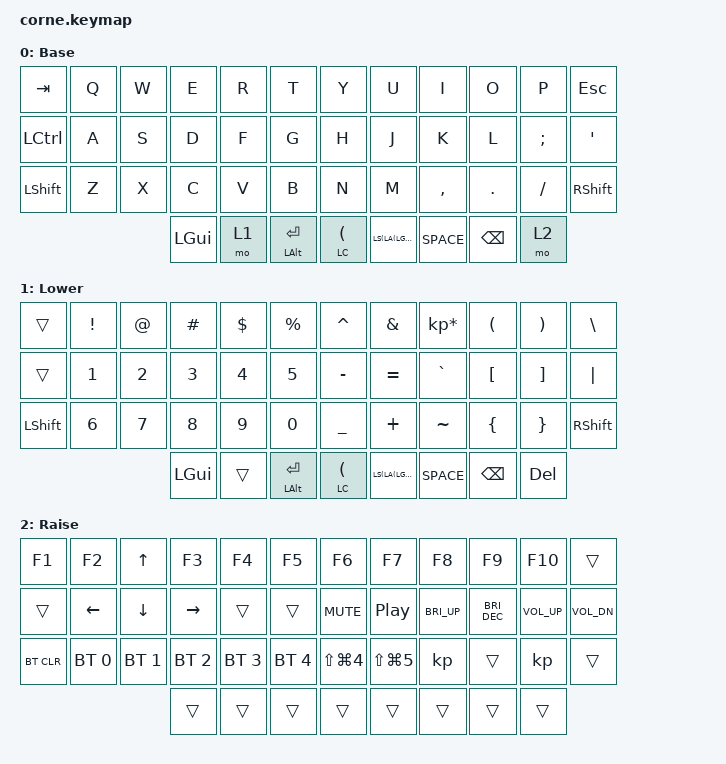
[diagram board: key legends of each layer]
/*
 * Copyright (c) 2020 The ZMK Contributors
 *
 * SPDX-License-Identifier: MIT
 */

#include <behaviors.dtsi>
#include <dt-bindings/zmk/keys.h>
#include <dt-bindings/zmk/bt.h>

/ {
    behaviors {
        tp: tap_preferred {
            compatible = "zmk,behavior-hold-tap";
            label = "TAP_PREFERRED";
            #binding-cells = <2>;
            tapping-term-ms = <150>;
            quick-tap-ms = <0>;
            flavor = "tap-preferred";
            bindings = <&kp>, <&kp>;
        }; 
    };

    keymap {
        compatible = "zmk,keymap";

        default_layer {
            // -----------------------------------------------------------------------------------------
            // | TAB  |  Q  |  W  |  E  |  R  |  T      |   |  Y        |  U   |  I  |  O  |  P  | ESC  |
            // | CTRL |  A  |  S  |  D  |  F  |  G      |   |  H        |  J   |  K  |  L  |  ;  |  SQT |
            // | SHFL |  Z  |  X  |  C  |  V  |  B      |   |  N        |  M   |  ,  |  .  |  /  | SHFR |
            //                    | GUI | LWR | ALT/ENT |   | HYPER/SPC | BKSP | RSE |

            label = "Base";
            bindings = <
   &kp TAB   &kp Q   &kp W      &kp E   &kp R      &kp T            &kp Y   &kp U      &kp I      &kp O     &kp P       &kp ESC
   &kp LCTRL &kp A   &kp S      &kp D   &kp F      &kp G            &kp H   &kp J      &kp K      &kp L     &kp SEMI    &kp SQT
   &kp LSHFT &kp Z   &kp X      &kp C   &kp V      &kp B            &kp N   &kp M      &kp COMMA  &kp DOT   &kp FSLH    &kp RSHIFT
                            &kp LGUI &mo 1 &tp LALT RET            &tp LC(LS(LA(LGUI))) SPACE &kp BSPC &mo 2
            >;
        };

        layer_below {
           // -----------------------------------------------------------------------------------------
           // |      |  !  |  @  |  #  |  $  |    %     |   |  ^          |  &   |  *  |  (  |  )  |   \   |
           // |      |  1  |  2  |  3  |  4  |    5     |   |  -          |  =   |  `  |  [  |  ]  |  "|"  |
           // | SHFT |  6  |  7  |  8  |  9  |    0     |   |  _          |  +   |  ~  |  {  |  }  | RSHFT |
           //                    | GUI |     | ALT/ENT  |   | HYPER/SPACE | BKSP | DEL |

            label = "Lower";
            bindings = <
   &trans       &kp EXCL &kp AT &kp HASH &kp DLLR &kp PRCNT       &kp CARET  &kp AMPS  &kp KP_MULTIPLY &kp LPAR &kp RPAR &kp BSLH
   &trans       &kp N1   &kp N2 &kp N3   &kp N4   &kp N5          &kp MINUS  &kp EQUAL &kp GRAVE       &kp LBKT &kp RBKT &kp PIPE
   &kp    LSHFT &kp N6   &kp N7 &kp N8   &kp N9   &kp N0          &kp UNDER  &kp PLUS  &kp TILDE       &kp LBRC &kp RBRC &kp RSHFT
                         &kp LGUI &trans &tp LALT RET             &tp LC(LS(LA(LGUI))) SPACE &kp BSPC  &kp DEL
            >;
        };

        layer_above {
            // -----------------------------------------------------------------------------------------
            // |   F1  |  F2  |  UP  |  F3   |  F4   |  F5        |   | F6                     |  F7                 |  F8       |  F9       |  F10   |        |
            // |       | LFT  | DWN  | RIGHT |       |            |   | MUTE                   | Play/Pause          | BRI+      |  BRI-     |  Vol + | Vol -  |
            // | BTCLR | BT1  | BT2  | BT3   | BT4   | BT5        |   | Capture screen portion | Screen recorder     |           |           |        |        |
            //                       |       |       |            |   |                        |                     |           |

            label = "Raise";
            bindings = <
   &kp    F1  &kp F2        &kp UP         &kp F3      &kp F4        &kp  F5      &kp  F6          &kp  F7           &kp  F8         &kp  F9         &kp  F10       &trans
   &trans     &kp LEFT      &kp DOWN       &kp RIGHT       &trans         &trans  &kp  C_MUTE      &kp  C_PP         &kp  C_BRI_UP   &kp  C_BRI_DEC  &kp  C_VOL_UP  &kp  C_VOL_DN  
   &bt BT_CLR &bt BT_SEL 0  &bt BT_SEL 1 &bt BT_SEL 2 &bt BT_SEL 3 &bt BT_SEL 4   &kp  LS(LG(NUMBER_4))   &kp  LS(LG(NUMBER_5))    &kp  &trans   &kp  &trans        &trans    &trans
                                                         &trans  &trans  &trans    &trans   &trans   &trans
            >;
        };
    };
};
